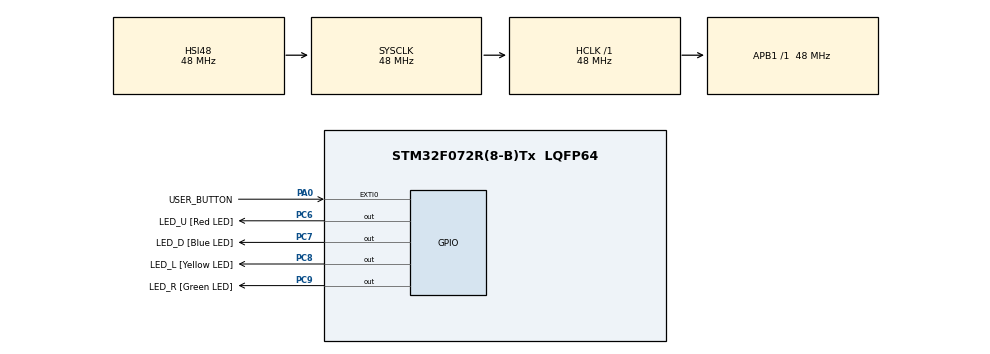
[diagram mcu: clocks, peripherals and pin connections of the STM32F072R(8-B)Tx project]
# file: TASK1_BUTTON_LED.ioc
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Mcu.Family=STM32F0
Mcu.Name=STM32F072R(8-B)Tx
Mcu.Package=LQFP64
NVIC.EXTI0_1_IRQn=true\:0\:0\:false\:false\:true\:true\:true\:true
PA0.GPIO_Label=USER_BUTTON
PA0.GPIO_ModeDefaultEXTI=GPIO_MODE_IT_RISING_FALLING
PA0.Signal=GPXTI0
PA13.Mode=Serial_Wire
PA13.Signal=SYS_SWDIO
PA14.Mode=Serial_Wire
PA14.Signal=SYS_SWCLK
PC6.GPIO_Label=LED_U [Red LED]
PC6.Signal=GPIO_Output
PC7.GPIO_Label=LED_D [Blue LED]
PC7.Signal=GPIO_Output
PC8.GPIO_Label=LED_L [Yellow LED]
PC8.Signal=GPIO_Output
PC9.GPIO_Label=LED_R [Green LED]
PC9.Signal=GPIO_Output
PF0-OSC_IN.Mode=HSE-External-Oscillator
PF0-OSC_IN.Signal=RCC_OSC_IN
PF1-OSC_OUT.Mode=HSE-External-Oscillator
PF1-OSC_OUT.Signal=RCC_OSC_OUT
ProjectManager.HeapSize=0x200
ProjectManager.StackSize=0x400
ProjectManager.TargetToolchain=STM32CubeIDE
RCC.AHBFreq_Value=48000000
RCC.APB1Freq_Value=48000000
RCC.APB1TimFreq_Value=48000000
RCC.HCLKFreq_Value=48000000
RCC.SYSCLKFreq_VALUE=48000000
RCC.SYSCLKSource=RCC_SYSCLKSOURCE_HSI48
board=custom

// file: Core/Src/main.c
/* USER CODE BEGIN Header */
/**
 ******************************************************************************
 * @file           : main.c
 * @brief          : Main program body
 ******************************************************************************
 * @attention
 *
 * Copyright (c) 2023 STMicroelectronics.
 * All rights reserved.
 *
 * This software is licensed under terms that can be found in the LICENSE file
 * in the root directory of this software component.
 * If no LICENSE file comes with this software, it is provided AS-IS.
 *
 ******************************************************************************
 */
/* USER CODE END Header */
#include "main.h"

/* USER CODE BEGIN Includes */
#include <stdbool.h>
/* USER CODE END Includes */

void SystemClock_Config(void);
static void MX_GPIO_Init(void);

int main(void)
{

	/* MCU Configuration--------------------------------------------------------*/

	/* Reset of all peripherals, Initializes the Flash interface and the Systick. */
	HAL_Init();

	/* Configure the system clock */
	SystemClock_Config();

	/* Initialize all configured peripherals */
	MX_GPIO_Init();

	/* Infinite loop */
	/* USER CODE BEGIN WHILE */
	while (1)
	{
		bool mode = 0;
		/* USER CODE END WHILE */
		switch (key_flag)
		{
		case NO_PRESS:
		{
		}
			break;
		case SHORT_PRESS:
		{
			key_flag = NO_PRESS;
			// Действите на короткое нажатие - бегущие огни по часовой
			HAL_GPIO_WritePin(GPIOC, LED_R_Pin, GPIO_PIN_SET);
			HAL_GPIO_WritePin(GPIOC, LED_D_Pin, GPIO_PIN_RESET);
			HAL_GPIO_WritePin(GPIOC, LED_L_Pin, GPIO_PIN_RESET);
			HAL_GPIO_WritePin(GPIOC, LED_U_Pin, GPIO_PIN_RESET);
			HAL_Delay(100);

			HAL_GPIO_WritePin(GPIOC, LED_R_Pin, GPIO_PIN_RESET);
			HAL_GPIO_WritePin(GPIOC, LED_D_Pin, GPIO_PIN_SET);
			HAL_GPIO_WritePin(GPIOC, LED_L_Pin, GPIO_PIN_RESET);
			HAL_GPIO_WritePin(GPIOC, LED_U_Pin, GPIO_PIN_RESET);
			HAL_Delay(100);

			HAL_GPIO_WritePin(GPIOC, LED_R_Pin, GPIO_PIN_RESET);
			HAL_GPIO_WritePin(GPIOC, LED_D_Pin, GPIO_PIN_RESET);
			HAL_GPIO_WritePin(GPIOC, LED_L_Pin, GPIO_PIN_SET);
			HAL_GPIO_WritePin(GPIOC, LED_U_Pin, GPIO_PIN_RESET);
			HAL_Delay(100);

			HAL_GPIO_WritePin(GPIOC, LED_R_Pin, GPIO_PIN_RESET);
			HAL_GPIO_WritePin(GPIOC, LED_D_Pin, GPIO_PIN_RESET);
			HAL_GPIO_WritePin(GPIOC, LED_L_Pin, GPIO_PIN_RESET);
			HAL_GPIO_WritePin(GPIOC, LED_U_Pin, GPIO_PIN_SET);
			HAL_Delay(100);

			HAL_GPIO_WritePin(GPIOC, LED_R_Pin, GPIO_PIN_RESET);
			HAL_GPIO_WritePin(GPIOC, LED_D_Pin, GPIO_PIN_RESET);
			HAL_GPIO_WritePin(GPIOC, LED_L_Pin, GPIO_PIN_RESET);
			HAL_GPIO_WritePin(GPIOC, LED_U_Pin, GPIO_PIN_RESET);
		}
			break;
		case LONG_PRESS:
		{
			key_flag = NO_PRESS;
			// Действите на длинное нажатие - бегущие огни против часовой
			HAL_GPIO_WritePin(GPIOC, LED_R_Pin, GPIO_PIN_SET);
			HAL_GPIO_WritePin(GPIOC, LED_D_Pin, GPIO_PIN_RESET);
			HAL_GPIO_WritePin(GPIOC, LED_L_Pin, GPIO_PIN_RESET);
			HAL_GPIO_WritePin(GPIOC, LED_U_Pin, GPIO_PIN_RESET);
			HAL_Delay(100);

			HAL_GPIO_WritePin(GPIOC, LED_R_Pin, GPIO_PIN_RESET);
			HAL_GPIO_WritePin(GPIOC, LED_D_Pin, GPIO_PIN_RESET);
			HAL_GPIO_WritePin(GPIOC, LED_L_Pin, GPIO_PIN_RESET);
			HAL_GPIO_WritePin(GPIOC, LED_U_Pin, GPIO_PIN_SET);
			HAL_Delay(100);

			HAL_GPIO_WritePin(GPIOC, LED_R_Pin, GPIO_PIN_RESET);
			HAL_GPIO_WritePin(GPIOC, LED_D_Pin, GPIO_PIN_RESET);
			HAL_GPIO_WritePin(GPIOC, LED_L_Pin, GPIO_PIN_SET);
			HAL_GPIO_WritePin(GPIOC, LED_U_Pin, GPIO_PIN_RESET);
			HAL_Delay(100);

			HAL_GPIO_WritePin(GPIOC, LED_R_Pin, GPIO_PIN_RESET);
			HAL_GPIO_WritePin(GPIOC, LED_D_Pin, GPIO_PIN_SET);
			HAL_GPIO_WritePin(GPIOC, LED_L_Pin, GPIO_PIN_RESET);
			HAL_GPIO_WritePin(GPIOC, LED_U_Pin, GPIO_PIN_RESET);
			HAL_Delay(100);

			HAL_GPIO_WritePin(GPIOC, LED_R_Pin, GPIO_PIN_RESET);
			HAL_GPIO_WritePin(GPIOC, LED_D_Pin, GPIO_PIN_RESET);
			HAL_GPIO_WritePin(GPIOC, LED_L_Pin, GPIO_PIN_RESET);
			HAL_GPIO_WritePin(GPIOC, LED_U_Pin, GPIO_PIN_RESET);
		}
			break;
		case MAX_PRESS:
		{
			if (mode == 0)
			{
				HAL_GPIO_WritePin(GPIOC, LED_R_Pin, GPIO_PIN_RESET);
				HAL_GPIO_WritePin(GPIOC, LED_D_Pin, GPIO_PIN_RESET);
				HAL_GPIO_WritePin(GPIOC, LED_L_Pin, GPIO_PIN_RESET);
				HAL_GPIO_WritePin(GPIOC, LED_U_Pin, GPIO_PIN_SET);
				HAL_Delay(100);

				HAL_GPIO_WritePin(GPIOC, LED_R_Pin, GPIO_PIN_RESET);
				HAL_GPIO_WritePin(GPIOC, LED_D_Pin, GPIO_PIN_SET);
				HAL_GPIO_WritePin(GPIOC, LED_L_Pin, GPIO_PIN_RESET);
				HAL_GPIO_WritePin(GPIOC, LED_U_Pin, GPIO_PIN_RESET);
				HAL_Delay(100);

				HAL_GPIO_WritePin(GPIOC, LED_R_Pin, GPIO_PIN_SET);
				HAL_GPIO_WritePin(GPIOC, LED_D_Pin, GPIO_PIN_RESET);
				HAL_GPIO_WritePin(GPIOC, LED_L_Pin, GPIO_PIN_RESET);
				HAL_GPIO_WritePin(GPIOC, LED_U_Pin, GPIO_PIN_RESET);
				HAL_Delay(100);

				HAL_GPIO_WritePin(GPIOC, LED_R_Pin, GPIO_PIN_RESET);
				HAL_GPIO_WritePin(GPIOC, LED_D_Pin, GPIO_PIN_RESET);
				HAL_GPIO_WritePin(GPIOC, LED_L_Pin, GPIO_PIN_SET);
				HAL_GPIO_WritePin(GPIOC, LED_U_Pin, GPIO_PIN_RESET);
				HAL_Delay(100);

				HAL_GPIO_WritePin(GPIOC, LED_R_Pin, GPIO_PIN_RESET);
				HAL_GPIO_WritePin(GPIOC, LED_D_Pin, GPIO_PIN_RESET);
				HAL_GPIO_WritePin(GPIOC, LED_L_Pin, GPIO_PIN_RESET);
				HAL_GPIO_WritePin(GPIOC, LED_U_Pin, GPIO_PIN_RESET);
			}
			else
			{
				key_flag = NO_PRESS;
				mode = !mode;
			}
		}
			break;
		}
	}
}

void SystemClock_Config(void)
{
	RCC_OscInitTypeDef RCC_OscInitStruct =
	{ 0 };
	RCC_ClkInitTypeDef RCC_ClkInitStruct =
	{ 0 };

	/** Initializes the RCC Oscillators according to the specified parameters
	 * in the RCC_OscInitTypeDef structure.
	 */
	RCC_OscInitStruct.OscillatorType = RCC_OSCILLATORTYPE_HSI48;
	RCC_OscInitStruct.HSI48State = RCC_HSI48_ON;
	RCC_OscInitStruct.PLL.PLLState = RCC_PLL_NONE;
	if (HAL_RCC_OscConfig(&RCC_OscInitStruct) != HAL_OK)
	{
		Error_Handler();
	}

	/** Initializes the CPU, AHB and APB buses clocks
	 */
	RCC_ClkInitStruct.ClockType = RCC_CLOCKTYPE_HCLK | RCC_CLOCKTYPE_SYSCLK
			| RCC_CLOCKTYPE_PCLK1;
	RCC_ClkInitStruct.SYSCLKSource = RCC_SYSCLKSOURCE_HSI48;
	RCC_ClkInitStruct.AHBCLKDivider = RCC_SYSCLK_DIV1;
	RCC_ClkInitStruct.APB1CLKDivider = RCC_HCLK_DIV1;

	if (HAL_RCC_ClockConfig(&RCC_ClkInitStruct, FLASH_LATENCY_1) != HAL_OK)
	{
		Error_Handler();
	}
}

static void MX_GPIO_Init(void)
{
	GPIO_InitTypeDef GPIO_InitStruct =
	{ 0 };

	/* GPIO Ports Clock Enable */
	__HAL_RCC_GPIOF_CLK_ENABLE();
	__HAL_RCC_GPIOA_CLK_ENABLE();
	__HAL_RCC_GPIOC_CLK_ENABLE();

	/*Configure GPIO pin Output Level */
	HAL_GPIO_WritePin(GPIOC, LED_U_Pin | LED_D_Pin | LED_L_Pin | LED_R_Pin,
			GPIO_PIN_RESET);

	/*Configure GPIO pin : USER_BUTTON_Pin */
	GPIO_InitStruct.Pin = USER_BUTTON_Pin;
	GPIO_InitStruct.Mode = GPIO_MODE_IT_RISING_FALLING;
	GPIO_InitStruct.Pull = GPIO_NOPULL;
	HAL_GPIO_Init(USER_BUTTON_GPIO_Port, &GPIO_InitStruct);

	/*Configure GPIO pins : LED_U_Pin LED_D_Pin LED_L_Pin LED_R_Pin */
	GPIO_InitStruct.Pin = LED_U_Pin | LED_D_Pin | LED_L_Pin | LED_R_Pin;
	GPIO_InitStruct.Mode = GPIO_MODE_OUTPUT_PP;
	GPIO_InitStruct.Pull = GPIO_NOPULL;
	GPIO_InitStruct.Speed = GPIO_SPEED_FREQ_LOW;
	HAL_GPIO_Init(GPIOC, &GPIO_InitStruct);

	/* EXTI interrupt init*/
	HAL_NVIC_SetPriority(EXTI0_1_IRQn, 0, 0);
	HAL_NVIC_EnableIRQ(EXTI0_1_IRQn);

}

void Error_Handler(void)
{
	__disable_irq();
	while (1)
	{
	}
}
